AUTOSAR XML (schema 4-2-2)
package /ComponentTypes
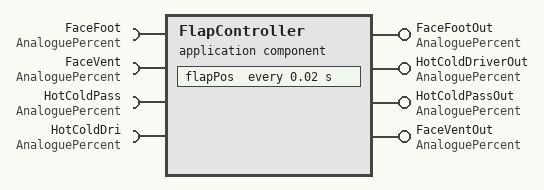
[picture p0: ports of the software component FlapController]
  application sw component type FlapController
    4 x require port, all with nonqueued-receiver-com-spec{data-element=flapSettingPercent, init-value=0}, required-interface=AnaloguePercent:
      FaceFoot
      FaceVent
      HotColdPass
      HotColdDri
    4 x provide port, all with nonqueued-sender-com-spec{data-element=flapSettingPercent, init-value=0}, provided-interface=AnaloguePercent:
      FaceFootOut
      HotColdDriverOut
      HotColdPassOut
      FaceVentOut
    behavior FlapController_InternalBehavior: data-type-mapping=flapMapSet
      4 x data received event, all with start-on-event=flapPos:
        DRT_flapPos_FaceFoot_flapSettingPercent: data=FaceFoot.flapSettingPercent
        DRT_flapPos_FaceVent_flapSettingPercent: data=FaceVent.flapSettingPercent
        DRT_flapPos_HotColdDri_flapSettingPercent: data=HotColdDri.flapSettingPercent
        DRT_flapPos_HotColdPass_flapSettingPercent: data=HotColdPass.flapSettingPercent
      timing event TMT_flapPos: start-on-event=flapPos, period=0.02
      runnable flapPos
        data-receive-point-by-arguments:
          4 x access:
            REC_FaceFoot_flapSettingPercent: accessed-variable=FaceFoot.flapSettingPercent
            REC_FaceVent_flapSettingPercent: accessed-variable=FaceVent.flapSettingPercent
            REC_HotColdDri_flapSettingPercent: accessed-variable=HotColdDri.flapSettingPercent
            REC_HotColdPass_flapSettingPercent: accessed-variable=HotColdPass.flapSettingPercent
        data-send-points:
          4 x access:
            SEND_FaceFootOut_flapSettingPercent: accessed-variable=FaceFootOut.flapSettingPercent
            SEND_FaceVentOut_flapSettingPercent: accessed-variable=FaceVentOut.flapSettingPercent
            SEND_HotColdDriverOut_flapSettingPercent: accessed-variable=HotColdDriverOut.flapSettingPercent
            SEND_HotColdPassOut_flapSettingPercent: accessed-variable=HotColdPassOut.flapSettingPercent
  swc implementation FlapController_Implementation: behavior=FlapController_InternalBehavior
